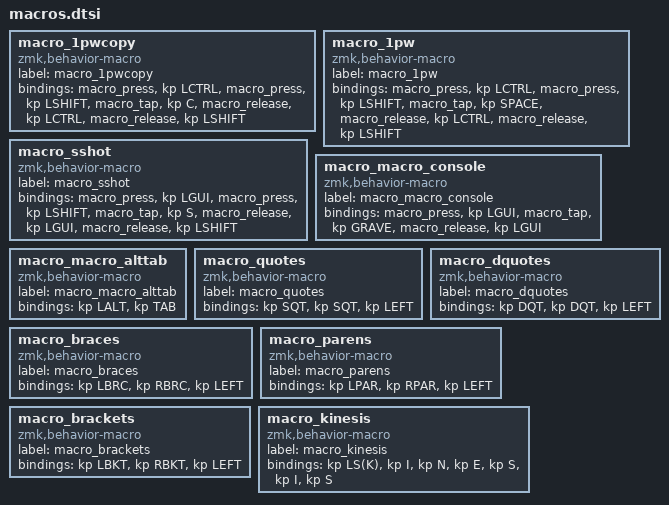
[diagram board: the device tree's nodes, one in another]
macro_1pwcopy: macro_1pwcopy{
compatible = "zmk,behavior-macro";
label = "macro_1pwcopy";
#binding-cells = <0>;
bindings = <&macro_press &kp LCTRL>, <&macro_press &kp LSHIFT>, <&macro_tap &kp C>, <&macro_release &kp LCTRL>, <&macro_release &kp LSHIFT>;
};
macro_1pw: macro_1pw{
compatible = "zmk,behavior-macro";
label = "macro_1pw";
#binding-cells = <0>;
bindings = <&macro_press &kp LCTRL>, <&macro_press &kp LSHIFT>, <&macro_tap &kp SPACE>, <&macro_release &kp LCTRL>, <&macro_release &kp LSHIFT>;
};
macro_sshot: macro_sshot{
compatible = "zmk,behavior-macro";
label = "macro_sshot";
#binding-cells = <0>;
bindings = <&macro_press &kp LGUI>, <&macro_press &kp LSHIFT>, <&macro_tap &kp S>, <&macro_release &kp LGUI>, <&macro_release &kp LSHIFT>;
};
macro_macro_console: macro_macro_console{
compatible = "zmk,behavior-macro";
label = "macro_macro_console";
#binding-cells = <0>;
bindings = <&macro_press &kp LGUI>, <&macro_tap &kp GRAVE>, <&macro_release &kp LGUI>;
};
macro_macro_alttab: macro_macro_alttab{
compatible = "zmk,behavior-macro";
label = "macro_macro_alttab";
#binding-cells = <0>;
bindings = <&kp LALT>, <&kp TAB>;
};
macro_quotes: macro_quotes{
compatible = "zmk,behavior-macro";
label = "macro_quotes";
#binding-cells = <0>;
bindings = <&kp SQT>, <&kp SQT>, <&kp LEFT>;
};
macro_dquotes: macro_dquotes{
compatible = "zmk,behavior-macro";
label = "macro_dquotes";
#binding-cells = <0>;
bindings = <&kp DQT>, <&kp DQT>, <&kp LEFT>;
};
macro_braces: macro_braces{
compatible = "zmk,behavior-macro";
label = "macro_braces";
#binding-cells = <0>;
bindings = <&kp LBRC>, <&kp RBRC>, <&kp LEFT>;
};
macro_parens: macro_parens{
compatible = "zmk,behavior-macro";
label = "macro_parens";
#binding-cells = <0>;
bindings = <&kp LPAR>, <&kp RPAR>, <&kp LEFT>;
};
macro_brackets: macro_brackets{
compatible = "zmk,behavior-macro";
label = "macro_brackets";
#binding-cells = <0>;
bindings = <&kp LBKT>, <&kp RBKT>, <&kp LEFT>;
};
macro_kinesis: macro_kinesis{
compatible = "zmk,behavior-macro";
label = "macro_kinesis";
#binding-cells = <0>;
bindings = <&kp LS(K)>, <&kp I>, <&kp N>, <&kp E>, <&kp S>, <&kp I>, <&kp S>;
};
